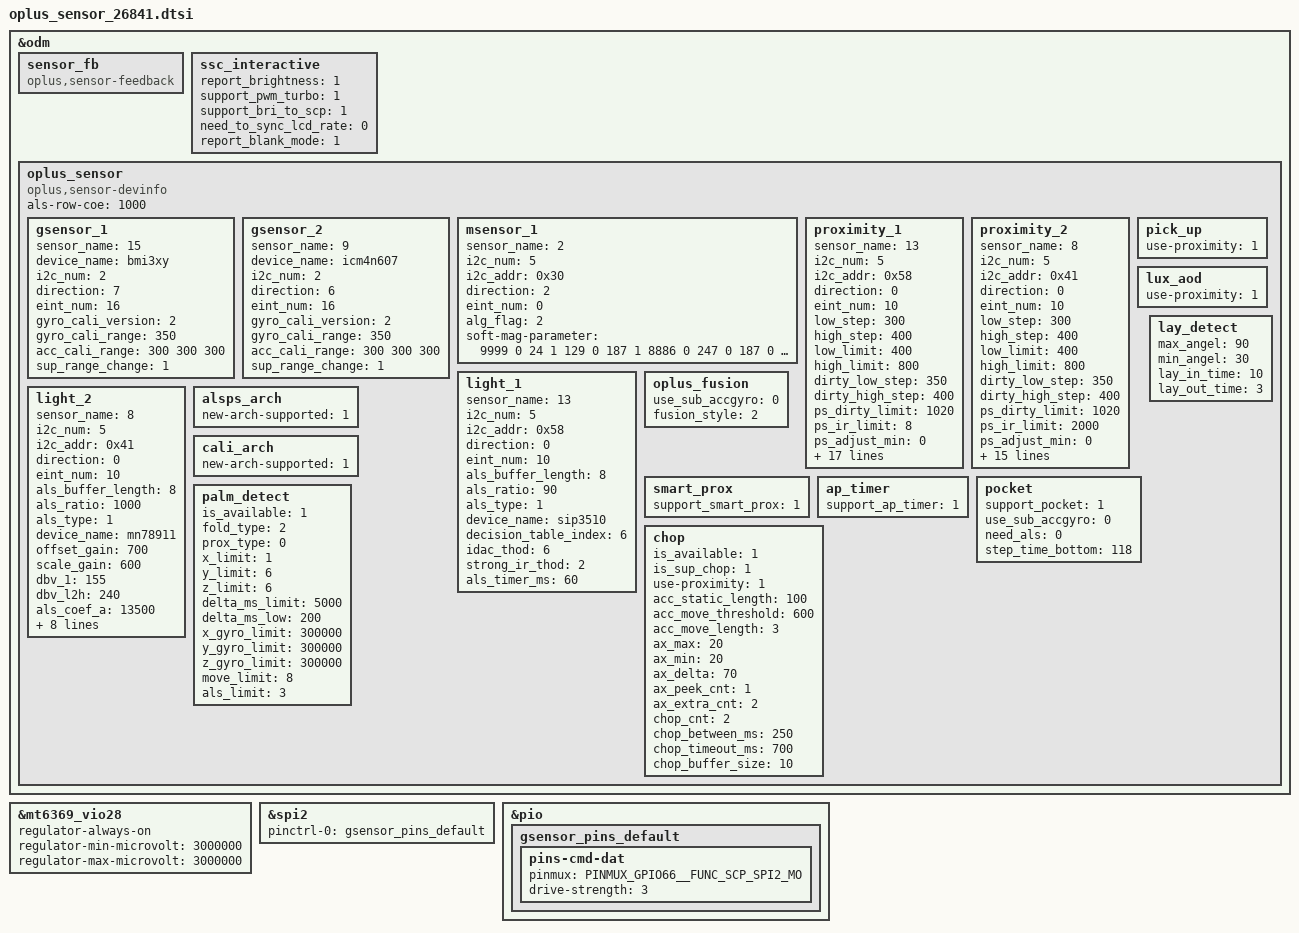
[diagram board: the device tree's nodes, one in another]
&odm {
	sensor_fb: sensor_fb {
		compatible = "oplus,sensor-feedback";
	};
	ssc_interactive: ssc_interactive {
		report_brightness = <1>;
		support_pwm_turbo = <1>;
		support_bri_to_scp = <1>;
		need_to_sync_lcd_rate = <0>;
		report_blank_mode = <1>;
	};
	oplus_sensor:oplus_sensor {
		compatible = "oplus,sensor-devinfo";
		als-row-coe = <1000>;
		/* sensor start */
		/*
		enum {
			LIS3DH,
			LSM6DS3,
			BMI160,
			LIS2HH12,
			LSM6DSM,
			BMI2XY,
			LSM6DSO,
			ICM4X6XX,
			ICM4263X,
			ICM4N607,
			BMI22X,
			SC7A20,
			MC34X9,
			BMA4XY,
			STK8329,
			BMI3XY,
			ICM456XY,
		};
		*/
		gsensor_1: gsensor_1 {
			status = "okay";
			sensor_name = <15>; // BMI3XY
			device_name = "bmi3xy";
			i2c_num = <2>;
			direction = <7>;
			eint_num = <16>;
			gyro_cali_version= <2>;
			gyro_cali_range =<350>;
			acc_cali_range= <300 300 300>;
			sup_range_change = <1>;
		};
		gsensor_2: gsensor_2 {
			status = "okay";
			sensor_name = <9>; // ICM4N607
			device_name = "icm4n607";
			i2c_num = <2>;
			direction = <6>;
			eint_num = <16>;
			gyro_cali_version= <2>;
			gyro_cali_range =<350>;
			acc_cali_range= <300 300 300>;
			sup_range_change = <1>;
		};

		/*
		enum {
			AKM09911,
			MMC3530,
			MMC5603,
			MXG4300,
			AKM09918,
			AKM09919,
		};
		*/
		msensor_1: msensor_1 {
			status = "okay";
			sensor_name = <2>; // MMC5603
			i2c_num = <5>;
			i2c_addr = <0x30>;
			direction = <2>;
			eint_num = <0>;
			alg_flag = <2>;
			soft-mag-parameter = <9999 0 24 1 129 0 187 1 8886 0 247 0 187 0 157 0 10709 0>;
		};
		/*
		enum {
			TMD2725,
			APSD9922,
			STK3335,
			STK3331,
			STK2232,
			TCS3701,
			STK32600,
			STK33502,
			MN78911,
			TCS3720,
			SIP3515,
			STK3329,
			LTR569,
			SIP3510,
			SIP3625,
			STK33C01,
			SIP3535,
			STK63701,
			TMD2765,
			TCS3743,
			SIP3511,
		};
		*/
		proximity_1: proximity_1 {
			status = "okay";
			sensor_name = <13>;//SIP3510
			i2c_num = <5>;
			i2c_addr = <0x58>;
			direction = <0>;
			eint_num = <10>;
			low_step = <300>;
			high_step = <400>;
			low_limit = <400>;
			high_limit = <800>;
			dirty_low_step = <350>;
			dirty_high_step = <400>;
			ps_dirty_limit = <1020>;
			ps_ir_limit = <8>;
			ps_adjust_min = <0>;
			ps_adjust_max = <2500>;
			sampling_count = <5>;
			step_max = <400>;
			step_min = <100>;
			step_div = <2000>;
			anti_shake_delta = <70>;
			dynamic_cali_max = <1024>;
			raw2offset_radio = <1000>;
			offset_max = <60000>;
			offset_range_min = <0>;
			offset_range_max = <65534>;
			force_cali_limit = <2000>;
			cali_jitter_limit = <50>;
			cal_offset_margin = <3000>;
			/* The bright light increment is set to a multiple of 100,
			   and the multiple is configured in the device tree. */
			hight_light_deala = <10>;
			drive_curr = <150>;
			ps_check_num = <10>;
		};
		proximity_2: proximity_2 {
			status = "okay";
			sensor_name = <8>;//MN78911
			i2c_num = <5>;
			i2c_addr = <0x41>;
			direction = <0>;
			eint_num = <10>;
			low_step = <300>;
			high_step = <400>;
			low_limit = <400>;
			high_limit = <800>;
			dirty_low_step = <350>;
			dirty_high_step = <400>;
			ps_dirty_limit = <1020>;
			ps_ir_limit = <2000>;
			ps_adjust_min = <0>;
			ps_adjust_max = <2350>;
			sampling_count = <5>;
			step_max = <400>;
			step_min = <100>;
			step_div = <2000>;
			anti_shake_delta = <70>;
			dynamic_cali_max = <2000>;
			raw2offset_radio = <1000>;
			offset_max = <60000>;
			offset_range_min = <0>;
			offset_range_max = <65534>;
			force_cali_limit = <2000>;
			cali_jitter_limit = <50>;
			cal_offset_margin = <3000>;
			ps_power_config = <1>;//ps_config
		};
		light_1: light_1 {
			status = "okay";
			sensor_name = <13>;//SIP3510
			i2c_num = <5>;
			i2c_addr = <0x58>;
			direction = <0>;
			eint_num = <10>;
			als_buffer_length =<8>;
			als_ratio = <90>;
			als_type = <1>;//<1-normal;2-under screen;3-normal needed compensation>
			device_name = "sip3510";
			decision_table_index = <6>;
			idac_thod = <6>;
			strong_ir_thod = <2>;
			als_timer_ms = <60>;
		};
		light_2: light_2 {
			status = "okay";
			sensor_name = <8>;//MN78911
			i2c_num = <5>;
			i2c_addr = <0x41>;
			direction = <0>;
			eint_num = <10>;
			als_buffer_length =<8>;
			als_ratio = <1000>;
			als_type = <1>;//<1-normal;2-under screen;3-normal needed compensation>
			device_name = "mn78911";
			offset_gain = <700>;
			scale_gain = <600>;
			dbv_1 = <155>;
			dbv_l2h = <240>;
			als_coef_a = <13500>;//a_ratio_thd
			als_coef_c = <100>;//cwf_ratio_thd
			als_coef_d = <7000>;//d65_ratio_thd
			ir_value0 = <758>;//a_factor
			ir_value1 = <750>;//d65_factor
			ir_value2 = <519>;//hz_factor
			ir_value3 = <169>;//lux_per_count
			atime = <1>;//als_config
			strong_ir_thod = <20000>;
		};

		pick_up: pick_up {
			status = "okay";
			use-proximity = <1>;
		};
		lux_aod: lux_aod {
			status = "okay";
			use-proximity = <1>;
		};
		alsps_arch: alsps_arch {
			status = "okay";
			new-arch-supported = <1>;
		};
		cali_arch: cali_arch {
			status = "okay";
			new-arch-supported = <1>;
		};
		oplus_fusion: oplus_fusion {
			status = "okay";
			use_sub_accgyro = <0>;
			fusion_style = <2>; // 0:vendor fusion; 1:oppo fusion; 2:mix fusion
		};
		smart_prox: smart_prox {
			status = "okay";
			support_smart_prox = <1>;
		};
		ap_timer: ap_timer {
			status = "okay";
			support_ap_timer = <1>;
		};
		pocket: pocket {
			status = "okay";
			support_pocket = <1>;
			use_sub_accgyro = <0>;
			need_als = <0>;
			step_time_bottom = <118>;
		};
		lay_detect: lay_detect{
			status = "okay";
			max_angel = <90>;
			min_angel = <30>;
			lay_in_time = <10>;
			lay_out_time = <3>;
		};
		palm_detect: palm_detect{
			status = "okay";
			is_available = <1>;
			fold_type = <2>;
			prox_type = <0>;
			x_limit = <1>;
			y_limit = <6>;
			z_limit = <6>;
			delta_ms_limit = <5000>;
			delta_ms_low = <200>;
			x_gyro_limit = <300000>;
			y_gyro_limit = <300000>;
			z_gyro_limit = <300000>;
			move_limit = <8>;
			als_limit = <3>;
		};
		chop: chop {
			status = "okay";
			is_available = <1>;
			is_sup_chop = <1>;
			use-proximity = <1>;

			acc_static_length = <100>;
			acc_move_threshold = <600>;
			acc_move_length = <3>;
			ax_max = <20>;
			ax_min = <20>;
			ax_delta = <70>;
			ax_peek_cnt = <1>;
			ax_extra_cnt = <2>;
			chop_cnt = <2>;
			chop_between_ms = <250>;
			chop_timeout_ms = <700>;
			chop_buffer_size = <10>;
		};
	};
/* sensor end */
};

/* ps led */
&mt6369_vio28 {
	regulator-always-on;
        regulator-min-microvolt = <3000000>;
        regulator-max-microvolt = <3000000>;
};
/*A+G spi drive current configuration*/
&spi2 {
	status = "okay";
	pinctrl-names = "default";
	pinctrl-0 = <&gsensor_pins_default>;
};

&pio {
	gsensor_pins_default: gsensor_pins_default {
		pins-cmd-dat {
			pinmux = <PINMUX_GPIO66__FUNC_SCP_SPI2_MO>;
			drive-strength = <3>;
		};
	};
};
